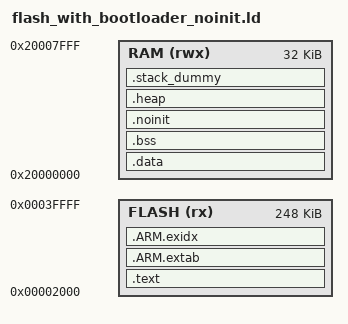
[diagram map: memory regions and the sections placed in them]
/*
  Repo-local copy of the Adafruit feather_m0 flash_with_bootloader.ld
  (framework-arduino-samd-adafruit/variants/feather_m0/linker_scripts/gcc/),
  with one addition: a NOLOAD `.noinit` output section between `.bss` and the
  heap. Variables tagged __attribute__((section(".noinit"))) land here and are
  NOT zeroed by the C runtime at startup, so they retain their value across a
  warm (watchdog/system) reset. Used by platform/ResetDiagnostics.cpp to carry a
  hang-zone breadcrumb through a WDT reboot. See
  documentation/Pending_Plans/RESET_REASON_DIAGNOSTICS.md.

  Only the node environments point board_build.ldscript here; the stock script
  is unchanged for base/other builds.
*/
MEMORY
{
  FLASH (rx) : ORIGIN = 0x00000000+0x2000, LENGTH = 0x00040000-0x2000 /* First 8KB used by bootloader */
  RAM (rwx) : ORIGIN = 0x20000000, LENGTH = 0x00008000
}

ENTRY(Reset_Handler)

SECTIONS
{
	.text :
	{
		__text_start__ = .;

		KEEP(*(.sketch_boot))

		. = ALIGN(0x2000);
		KEEP(*(.isr_vector))
		*(.text*)

		KEEP(*(.init))
		KEEP(*(.fini))

		/* .ctors */
		*crtbegin.o(.ctors)
		*crtbegin?.o(.ctors)
		*(EXCLUDE_FILE(*crtend?.o *crtend.o) .ctors)
		*(SORT(.ctors.*))
		*(.ctors)

		/* .dtors */
 		*crtbegin.o(.dtors)
 		*crtbegin?.o(.dtors)
 		*(EXCLUDE_FILE(*crtend?.o *crtend.o) .dtors)
 		*(SORT(.dtors.*))
 		*(.dtors)

		*(.rodata*)

		KEEP(*(.eh_frame*))
	} > FLASH

	.ARM.extab :
	{
		*(.ARM.extab* .gnu.linkonce.armextab.*)
	} > FLASH

	__exidx_start = .;
	.ARM.exidx :
	{
		*(.ARM.exidx* .gnu.linkonce.armexidx.*)
	} > FLASH
	__exidx_end = .;

	__etext = .;

	.data : AT (__etext)
	{
		__data_start__ = .;
		*(vtable)
		*(.data*)

		. = ALIGN(4);
		/* preinit data */
		PROVIDE_HIDDEN (__preinit_array_start = .);
		KEEP(*(.preinit_array))
		PROVIDE_HIDDEN (__preinit_array_end = .);

		. = ALIGN(4);
		/* init data */
		PROVIDE_HIDDEN (__init_array_start = .);
		KEEP(*(SORT(.init_array.*)))
		KEEP(*(.init_array))
		PROVIDE_HIDDEN (__init_array_end = .);


		. = ALIGN(4);
		/* finit data */
		PROVIDE_HIDDEN (__fini_array_start = .);
		KEEP(*(SORT(.fini_array.*)))
		KEEP(*(.fini_array))
		PROVIDE_HIDDEN (__fini_array_end = .);

		KEEP(*(.jcr*))
		. = ALIGN(16);
		/* All data end */
		__data_end__ = .;

	} > RAM

	.bss :
	{
		. = ALIGN(4);
		__bss_start__ = .;
		*(.bss*)
		*(COMMON)
		. = ALIGN(4);
		__bss_end__ = .;
	} > RAM

	/* Retained-across-warm-reset storage. NOLOAD so it occupies RAM address
	 * space but has no load image, and it is outside .bss so the startup code's
	 * bss-zero loop never touches it. */
	.noinit (NOLOAD) :
	{
		. = ALIGN(4);
		PROVIDE(__noinit_start__ = .);
		KEEP(*(.noinit))
		*(.noinit*)
		. = ALIGN(4);
		PROVIDE(__noinit_end__ = .);
	} > RAM

	.heap (COPY):
	{
		__end__ = .;
		PROVIDE(end = .);
		*(.heap*)
		__HeapLimit = .;
	} > RAM

	/* .stack_dummy section doesn't contains any symbols. It is only
	 * used for linker to calculate size of stack sections, and assign
	 * values to stack symbols later */
	.stack_dummy (COPY):
	{
		*(.stack*)
	} > RAM

	/* Set stack top to end of RAM, and stack limit move down by
	 * size of stack_dummy section */
	__StackTop = ORIGIN(RAM) + LENGTH(RAM);
	__StackLimit = __StackTop - SIZEOF(.stack_dummy);
	PROVIDE(__stack = __StackTop);

	__ram_end__ = ORIGIN(RAM) + LENGTH(RAM) -1 ;

	/* Check if data + heap + stack exceeds RAM limit */
	ASSERT(__StackLimit >= __HeapLimit, "region RAM overflowed with stack")
}
